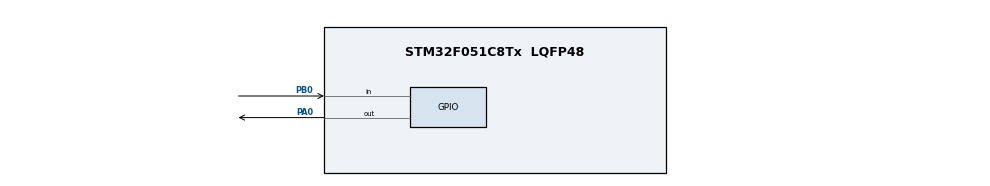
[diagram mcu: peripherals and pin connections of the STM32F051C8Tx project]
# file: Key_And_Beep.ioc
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Mcu.Family=STM32F0
Mcu.Name=STM32F051C8Tx
Mcu.Package=LQFP48
PA0.PinState=GPIO_PIN_SET
PA0.Signal=GPIO_Output
PB0.Signal=GPIO_Input
ProjectManager.HeapSize=0x200
ProjectManager.StackSize=0x400
ProjectManager.TargetToolchain=MDK-ARM V5
board=Key_And_Beep

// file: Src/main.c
/**
  ******************************************************************************
  * File Name          : main.c
  * Description        : Main program body
  ******************************************************************************
  *
  * COPYRIGHT(c) 2019 STMicroelectronics
  *
  * Redistribution and use in source and binary forms, with or without modification,
  * are permitted provided that the following conditions are met:
  *   1. Redistributions of source code must retain the above copyright notice,
  *      this list of conditions and the following disclaimer.
  *   2. Redistributions in binary form must reproduce the above copyright notice,
  *      this list of conditions and the following disclaimer in the documentation
  *      and/or other materials provided with the distribution.
  *   3. Neither the name of STMicroelectronics nor the names of its contributors
  *      may be used to endorse or promote products derived from this software
  *      without specific prior written permission.
  *
  * THIS SOFTWARE IS PROVIDED BY THE COPYRIGHT HOLDERS AND CONTRIBUTORS "AS IS"
  * AND ANY EXPRESS OR IMPLIED WARRANTIES, INCLUDING, BUT NOT LIMITED TO, THE
  * IMPLIED WARRANTIES OF MERCHANTABILITY AND FITNESS FOR A PARTICULAR PURPOSE ARE
  * DISCLAIMED. IN NO EVENT SHALL THE COPYRIGHT HOLDER OR CONTRIBUTORS BE LIABLE
  * FOR ANY DIRECT, INDIRECT, INCIDENTAL, SPECIAL, EXEMPLARY, OR CONSEQUENTIAL
  * DAMAGES (INCLUDING, BUT NOT LIMITED TO, PROCUREMENT OF SUBSTITUTE GOODS OR
  * SERVICES; LOSS OF USE, DATA, OR PROFITS; OR BUSINESS INTERRUPTION) HOWEVER
  * CAUSED AND ON ANY THEORY OF LIABILITY, WHETHER IN CONTRACT, STRICT LIABILITY,
  * OR TORT (INCLUDING NEGLIGENCE OR OTHERWISE) ARISING IN ANY WAY OUT OF THE USE
  * OF THIS SOFTWARE, EVEN IF ADVISED OF THE POSSIBILITY OF SUCH DAMAGE.
  *
  ******************************************************************************
  */
#include "stm32f0xx_hal.h"

/* USER CODE BEGIN PV */
/* Private variables ---------------------------------------------------------*/

/* USER CODE END PV */

void SystemClock_Config(void);
void Error_Handler(void);
static void MX_GPIO_Init(void);

/* USER CODE BEGIN PFP */
/* Private function prototypes -----------------------------------------------*/

/* USER CODE END PFP */

int main(void)
{

  /* USER CODE BEGIN 1 */
	int flag = 1;
  /* USER CODE END 1 */

  /* MCU Configuration----------------------------------------------------------*/

  /* Reset of all peripherals, Initializes the Flash interface and the Systick. */
  HAL_Init();

  /* Configure the system clock */
  SystemClock_Config();

  /* Initialize all configured peripherals */
  MX_GPIO_Init();

  /* Infinite loop */
  /* USER CODE BEGIN WHILE */
//  while (1)
//  {
  /* USER CODE END WHILE */
//		if(HAL_GPIO_ReadPin(GPIOB,GPIO_PIN_0) == 0)
//		{
//			HAL_Delay(10);
//			if(HAL_GPIO_ReadPin(GPIOB,GPIO_PIN_0) == 0)
//			{
//				if(flag == 0)
//				{
//					HAL_GPIO_WritePin(GPIOA,GPIO_PIN_0,GPIO_PIN_SET);
//					flag = 1;
//				}else{
//					HAL_GPIO_WritePin(GPIOA,GPIO_PIN_0,GPIO_PIN_RESET);
//					flag = 0;
//				}
//				while(HAL_GPIO_ReadPin(GPIOB,GPIO_PIN_0) == 0);
//			}
//		}
//		HAL_Delay(10);
//  /* USER CODE BEGIN 3 */

//  }
  /* USER CODE END 3 */
	while(1)
	{
		if(HAL_GPIO_ReadPin(GPIOB,GPIO_PIN_0) == 0)
		{
			HAL_Delay(10);
			{
				if(HAL_GPIO_ReadPin(GPIOB,GPIO_PIN_0) == 0)
				{
					HAL_GPIO_WritePin(GPIOA,GPIO_PIN_0,GPIO_PIN_RESET);
					while(HAL_GPIO_ReadPin(GPIOB,GPIO_PIN_0) == 0);
					HAL_GPIO_WritePin(GPIOA,GPIO_PIN_0,GPIO_PIN_SET);
				}
			}
		}
	}

}

/** System Clock Configuration
*/
void SystemClock_Config(void)
{

  RCC_OscInitTypeDef RCC_OscInitStruct;
  RCC_ClkInitTypeDef RCC_ClkInitStruct;

  RCC_OscInitStruct.OscillatorType = RCC_OSCILLATORTYPE_HSI;
  RCC_OscInitStruct.HSIState = RCC_HSI_ON;
  RCC_OscInitStruct.HSICalibrationValue = 16;
  RCC_OscInitStruct.PLL.PLLState = RCC_PLL_NONE;
  if (HAL_RCC_OscConfig(&RCC_OscInitStruct) != HAL_OK)
  {
    Error_Handler();
  }

  RCC_ClkInitStruct.ClockType = RCC_CLOCKTYPE_HCLK|RCC_CLOCKTYPE_SYSCLK
                              |RCC_CLOCKTYPE_PCLK1;
  RCC_ClkInitStruct.SYSCLKSource = RCC_SYSCLKSOURCE_HSI;
  RCC_ClkInitStruct.AHBCLKDivider = RCC_SYSCLK_DIV1;
  RCC_ClkInitStruct.APB1CLKDivider = RCC_HCLK_DIV1;
  if (HAL_RCC_ClockConfig(&RCC_ClkInitStruct, FLASH_LATENCY_0) != HAL_OK)
  {
    Error_Handler();
  }

  HAL_SYSTICK_Config(HAL_RCC_GetHCLKFreq()/1000);

  HAL_SYSTICK_CLKSourceConfig(SYSTICK_CLKSOURCE_HCLK);

  /* SysTick_IRQn interrupt configuration */
  HAL_NVIC_SetPriority(SysTick_IRQn, 0, 0);
}

/** Configure pins as
        * Analog
        * Input
        * Output
        * EVENT_OUT
        * EXTI
*/
static void MX_GPIO_Init(void)
{

  GPIO_InitTypeDef GPIO_InitStruct;

  /* GPIO Ports Clock Enable */
  __HAL_RCC_GPIOA_CLK_ENABLE();
  __HAL_RCC_GPIOB_CLK_ENABLE();

  /*Configure GPIO pin Output Level */
  HAL_GPIO_WritePin(GPIOA, GPIO_PIN_0, GPIO_PIN_SET);

  /*Configure GPIO pin : PA0 */
  GPIO_InitStruct.Pin = GPIO_PIN_0;
  GPIO_InitStruct.Mode = GPIO_MODE_OUTPUT_PP;
  GPIO_InitStruct.Pull = GPIO_NOPULL;
  GPIO_InitStruct.Speed = GPIO_SPEED_FREQ_LOW;
  HAL_GPIO_Init(GPIOA, &GPIO_InitStruct);

  /*Configure GPIO pin : PB0 */
  GPIO_InitStruct.Pin = GPIO_PIN_0;
  GPIO_InitStruct.Mode = GPIO_MODE_INPUT;
  GPIO_InitStruct.Pull = GPIO_NOPULL;
  HAL_GPIO_Init(GPIOB, &GPIO_InitStruct);

}

void Error_Handler(void)
{
  while(1)
  {
  }
}

/************************ (C) COPYRIGHT STMicroelectronics *****END OF FILE****/
